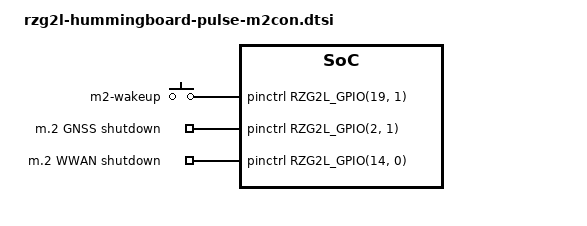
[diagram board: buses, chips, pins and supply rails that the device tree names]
// SPDX-License-Identifier: (GPL-2.0+ OR MIT)
/*
 * Copyright 2025 Josua Mayer <josua@solid-run.com>
 */

#include <dt-bindings/input/input.h>

/ {
	gpio-keys {
		compatible = "gpio-keys";

		wakeup-event {
			label = "m2-wakeup";
			interrupts-extended = <&pinctrl RZG2L_GPIO(19, 1) IRQ_TYPE_EDGE_FALLING>;
			linux,code = <KEY_WAKEUP>;
			wakeup-source;
		};
	};

	rfkill-m2-gnss {
		compatible = "rfkill-gpio";
		label = "m.2 GNSS";
		radio-type = "gps";
		/* rfkill-gpio inverts internally */
		shutdown-gpios = <&pinctrl RZG2L_GPIO(2, 1) GPIO_ACTIVE_HIGH>;
	};

	/* M.2 is B-keyed, so w-disable is for WWAN */
	rfkill-m2-wwan {
		compatible = "rfkill-gpio";
		label = "m.2 WWAN";
		radio-type = "wwan";
		/* rfkill-gpio inverts internally */
		shutdown-gpios = <&pinctrl RZG2L_GPIO(14, 0) GPIO_ACTIVE_HIGH>;
	};
};
